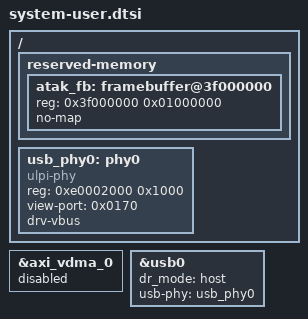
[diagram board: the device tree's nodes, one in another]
/include/ "system-conf.dtsi"
/ {
	/* A.T.A.K.: 16 MB at the top of the 1 GB DDR for the HDMI screen memory. Linux never uses it (no-map);
	   the VDMA reads the picture from 0x3F00_0000, user programs write it through /dev/mem. */
	reserved-memory {
		#address-cells = <1>;
		#size-cells = <1>;
		ranges;
		atak_fb: framebuffer@3f000000 {
			reg = <0x3f000000 0x01000000>;
			no-map;
		};
	};

	/* USB3320 ULPI PHY of the Zybo Z7 USB port (same as the Digilent Zybo Z7 device tree) */
	usb_phy0: phy0 {
		#phy-cells = <0>;
		compatible = "ulpi-phy";
		reg = <0xe0002000 0x1000>;
		view-port = <0x0170>;
		drv-vbus;
	};
};

/* The VDMA is programmed from user space (hdmi_test.sh, later the GUI), not by the Linux DMA driver. */
&axi_vdma_0 {
	status = "disabled";
};

/* USB port as host: mouse + keyboard for the GUI */
&usb0 {
	dr_mode = "host";
	usb-phy = <&usb_phy0>;
};
